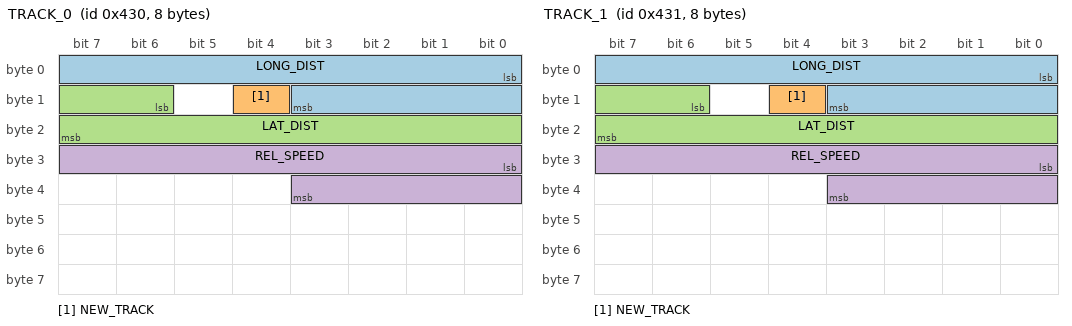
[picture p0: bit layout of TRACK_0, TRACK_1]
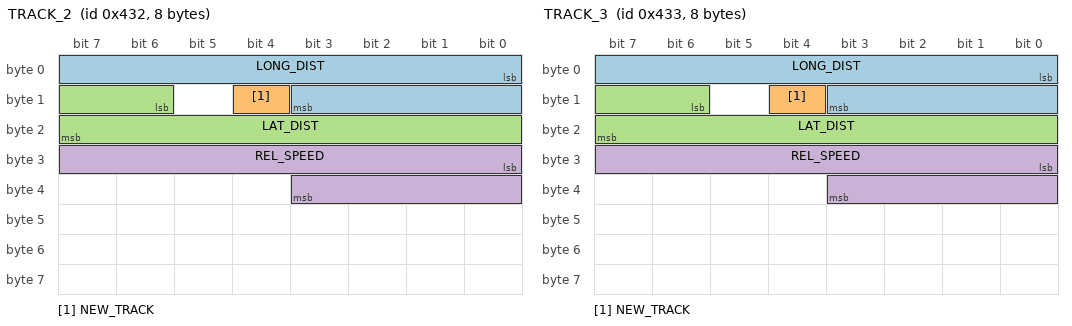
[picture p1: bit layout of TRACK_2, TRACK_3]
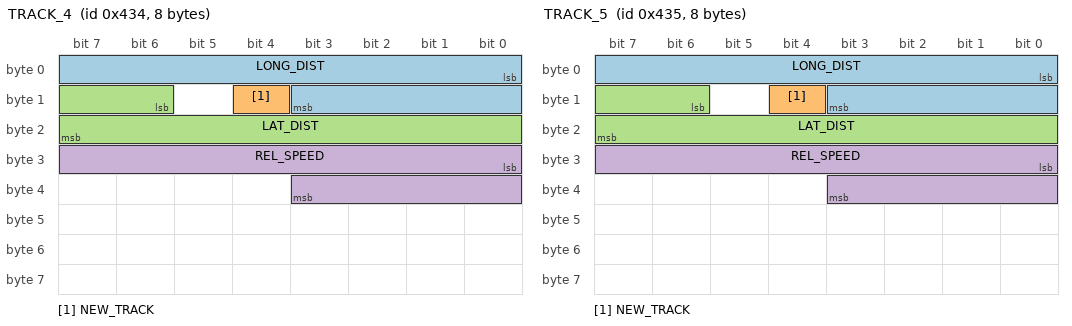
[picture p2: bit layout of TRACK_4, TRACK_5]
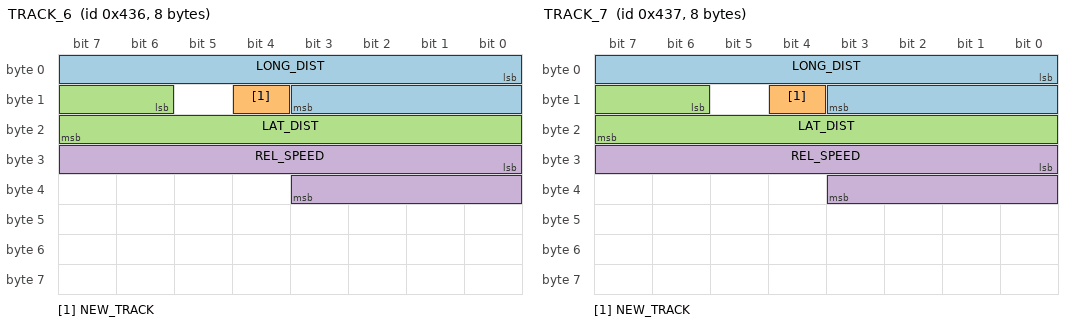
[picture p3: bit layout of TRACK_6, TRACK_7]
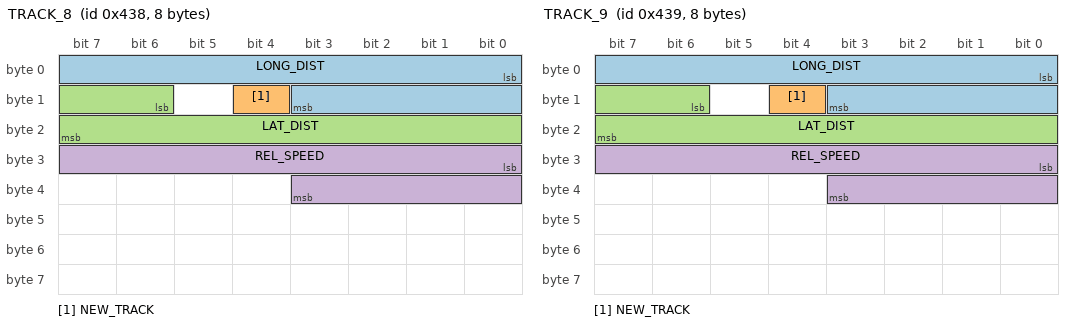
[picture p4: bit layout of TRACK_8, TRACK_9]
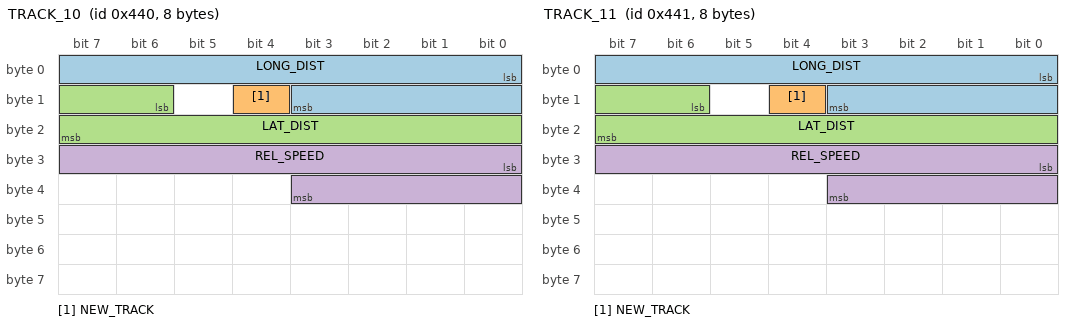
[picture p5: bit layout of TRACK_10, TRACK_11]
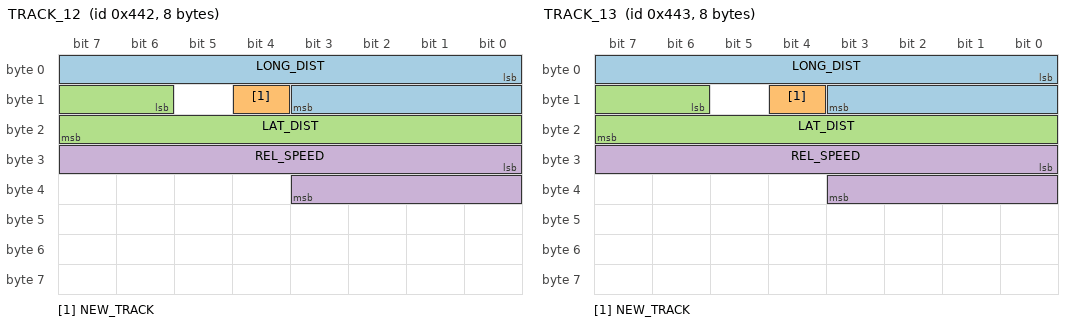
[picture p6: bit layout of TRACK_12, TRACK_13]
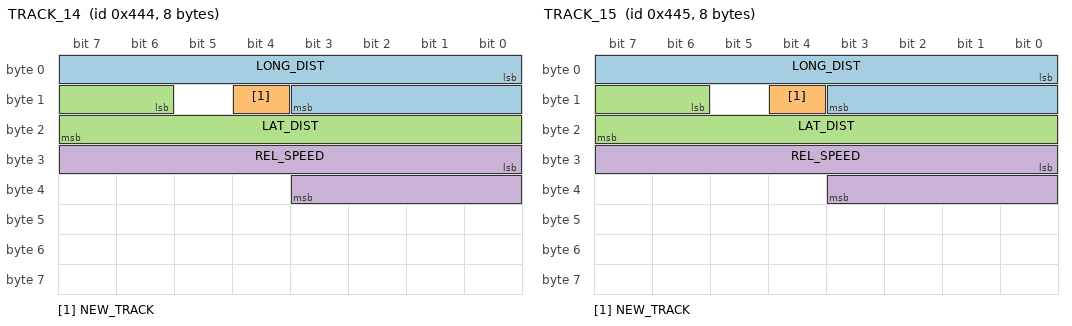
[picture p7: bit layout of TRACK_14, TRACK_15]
VERSION ""

NS_ :

BS_:

BO_ 0x300 VEHICLE_STATE: 8 ADAS
 SG_ SET_ME_XF9 : 0|8@1+ (1,0) [0|255] "" Vector__XXX
 SG_ VEHICLE_SPEED : 8|8@1+ (1,0) [0|255] "kph" Vector__XXX

BO_ 0x301 VEHICLE_STATE2: 8 ADAS
 SG_ SET_ME_0F18510 : 0|28@1+ (1,0) [0|268435455] "" Vector__XXX
 SG_ SET_ME_25A0000 : 28|28@1+ (1,0) [0|268435455] "" Vector__XXX

BO_ 0x400 XXX: 8 RADAR

BO_ 0x410 XXX: 8 RADAR

BO_ 0x411 XXX: 8 RADAR

BO_ 0x412 XXX: 8 RADAR

BO_ 0x413 XXX: 8 RADAR

BO_ 0x414 XXX: 8 RADAR

BO_ 0x415 XXX: 8 RADAR

BO_ 0x416 XXX: 8 RADAR

BO_ 0x417 XXX: 8 RADAR

BO_ 0x420 XXX: 8 RADAR

BO_ 0x421 XXX: 8 RADAR

BO_ 0x422 XXX: 8 RADAR

BO_ 0x423 XXX: 8 RADAR

BO_ 0x424 XXX: 8 RADAR

BO_ 0x430 TRACK_0: 8 RADAR
 SG_ LONG_DIST : 0|12@1+ (0.0625,0) [0|255.5] "m" Vector__XXX
 SG_ NEW_TRACK : 12|1@1+ (1,0) [0|1] "" Vector__XXX
 SG_ LAT_DIST : 14|10@1- (0.0625,0) [0|63.5] "m" Vector__XXX
 SG_ REL_SPEED : 24|12@1- (0.03125,0) [0|127.5] "m/s" Vector__XXX

BO_ 0x431 TRACK_1: 8 RADAR
 SG_ LONG_DIST : 0|12@1+ (0.0625,0) [0|255.5] "m" Vector__XXX
 SG_ NEW_TRACK : 12|1@1+ (1,0) [0|1] "" Vector__XXX
 SG_ LAT_DIST : 14|10@1- (0.0625,0) [0|63.5] "m" Vector__XXX
 SG_ REL_SPEED : 24|12@1- (0.03125,0) [0|127.5] "m/s" Vector__XXX

BO_ 0x432 TRACK_2: 8 RADAR
 SG_ LONG_DIST : 0|12@1+ (0.0625,0) [0|255.5] "m" Vector__XXX
 SG_ NEW_TRACK : 12|1@1+ (1,0) [0|1] "" Vector__XXX
 SG_ LAT_DIST : 14|10@1- (0.0625,0) [0|63.5] "m" Vector__XXX
 SG_ REL_SPEED : 24|12@1- (0.03125,0) [0|127.5] "m/s" Vector__XXX

BO_ 0x433 TRACK_3: 8 RADAR
 SG_ LONG_DIST : 0|12@1+ (0.0625,0) [0|255.5] "m" Vector__XXX
 SG_ NEW_TRACK : 12|1@1+ (1,0) [0|1] "" Vector__XXX
 SG_ LAT_DIST : 14|10@1- (0.0625,0) [0|63.5] "m" Vector__XXX
 SG_ REL_SPEED : 24|12@1- (0.03125,0) [0|127.5] "m/s" Vector__XXX

BO_ 0x434 TRACK_4: 8 RADAR
 SG_ LONG_DIST : 0|12@1+ (0.0625,0) [0|255.5] "m" Vector__XXX
 SG_ NEW_TRACK : 12|1@1+ (1,0) [0|1] "" Vector__XXX
 SG_ LAT_DIST : 14|10@1- (0.0625,0) [0|63.5] "m" Vector__XXX
 SG_ REL_SPEED : 24|12@1- (0.03125,0) [0|127.5] "m/s" Vector__XXX

BO_ 0x435 TRACK_5: 8 RADAR
 SG_ LONG_DIST : 0|12@1+ (0.0625,0) [0|255.5] "m" Vector__XXX
 SG_ NEW_TRACK : 12|1@1+ (1,0) [0|1] "" Vector__XXX
 SG_ LAT_DIST : 14|10@1- (0.0625,0) [0|63.5] "m" Vector__XXX
 SG_ REL_SPEED : 24|12@1- (0.03125,0) [0|127.5] "m/s" Vector__XXX

BO_ 0x436 TRACK_6: 8 RADAR
 SG_ LONG_DIST : 0|12@1+ (0.0625,0) [0|255.5] "m" Vector__XXX
 SG_ NEW_TRACK : 12|1@1+ (1,0) [0|1] "" Vector__XXX
 SG_ LAT_DIST : 14|10@1- (0.0625,0) [0|63.5] "m" Vector__XXX
 SG_ REL_SPEED : 24|12@1- (0.03125,0) [0|127.5] "m/s" Vector__XXX

BO_ 0x437 TRACK_7: 8 RADAR
 SG_ LONG_DIST : 0|12@1+ (0.0625,0) [0|255.5] "m" Vector__XXX
 SG_ NEW_TRACK : 12|1@1+ (1,0) [0|1] "" Vector__XXX
 SG_ LAT_DIST : 14|10@1- (0.0625,0) [0|63.5] "m" Vector__XXX
 SG_ REL_SPEED : 24|12@1- (0.03125,0) [0|127.5] "m/s" Vector__XXX

BO_ 0x438 TRACK_8: 8 RADAR
 SG_ LONG_DIST : 0|12@1+ (0.0625,0) [0|255.5] "m" Vector__XXX
 SG_ NEW_TRACK : 12|1@1+ (1,0) [0|1] "" Vector__XXX
 SG_ LAT_DIST : 14|10@1- (0.0625,0) [0|63.5] "m" Vector__XXX
 SG_ REL_SPEED : 24|12@1- (0.03125,0) [0|127.5] "m/s" Vector__XXX

BO_ 0x439 TRACK_9: 8 RADAR
 SG_ LONG_DIST : 0|12@1+ (0.0625,0) [0|255.5] "m" Vector__XXX
 SG_ NEW_TRACK : 12|1@1+ (1,0) [0|1] "" Vector__XXX
 SG_ LAT_DIST : 14|10@1- (0.0625,0) [0|63.5] "m" Vector__XXX
 SG_ REL_SPEED : 24|12@1- (0.03125,0) [0|127.5] "m/s" Vector__XXX

BO_ 0x440 TRACK_10: 8 RADAR
 SG_ LONG_DIST : 0|12@1+ (0.0625,0) [0|255.5] "m" Vector__XXX
 SG_ NEW_TRACK : 12|1@1+ (1,0) [0|1] "" Vector__XXX
 SG_ LAT_DIST : 14|10@1- (0.0625,0) [0|63.5] "m" Vector__XXX
 SG_ REL_SPEED : 24|12@1- (0.03125,0) [0|127.5] "m/s" Vector__XXX

BO_ 0x441 TRACK_11: 8 RADAR
 SG_ LONG_DIST : 0|12@1+ (0.0625,0) [0|255.5] "m" Vector__XXX
 SG_ NEW_TRACK : 12|1@1+ (1,0) [0|1] "" Vector__XXX
 SG_ LAT_DIST : 14|10@1- (0.0625,0) [0|63.5] "m" Vector__XXX
 SG_ REL_SPEED : 24|12@1- (0.03125,0) [0|127.5] "m/s" Vector__XXX

BO_ 0x442 TRACK_12: 8 RADAR
 SG_ LONG_DIST : 0|12@1+ (0.0625,0) [0|255.5] "m" Vector__XXX
 SG_ NEW_TRACK : 12|1@1+ (1,0) [0|1] "" Vector__XXX
 SG_ LAT_DIST : 14|10@1- (0.0625,0) [0|63.5] "m" Vector__XXX
 SG_ REL_SPEED : 24|12@1- (0.03125,0) [0|127.5] "m/s" Vector__XXX

BO_ 0x443 TRACK_13: 8 RADAR
 SG_ LONG_DIST : 0|12@1+ (0.0625,0) [0|255.5] "m" Vector__XXX
 SG_ NEW_TRACK : 12|1@1+ (1,0) [0|1] "" Vector__XXX
 SG_ LAT_DIST : 14|10@1- (0.0625,0) [0|63.5] "m" Vector__XXX
 SG_ REL_SPEED : 24|12@1- (0.03125,0) [0|127.5] "m/s" Vector__XXX

BO_ 0x444 TRACK_14: 8 RADAR
 SG_ LONG_DIST : 0|12@1+ (0.0625,0) [0|255.5] "m" Vector__XXX
 SG_ NEW_TRACK : 12|1@1+ (1,0) [0|1] "" Vector__XXX
 SG_ LAT_DIST : 14|10@1- (0.0625,0) [0|63.5] "m" Vector__XXX
 SG_ REL_SPEED : 24|12@1- (0.03125,0) [0|127.5] "m/s" Vector__XXX

BO_ 0x445 TRACK_15: 8 RADAR
 SG_ LONG_DIST : 0|12@1+ (0.0625,0) [0|255.5] "m" Vector__XXX
 SG_ NEW_TRACK : 12|1@1+ (1,0) [0|1] "" Vector__XXX
 SG_ LAT_DIST : 14|10@1- (0.0625,0) [0|63.5] "m" Vector__XXX
 SG_ REL_SPEED : 24|12@1- (0.03125,0) [0|127.5] "m/s" Vector__XXX

BO_ 0x4FF XXX: 8 RADAR

BO_ 0x500 XXX: 8 RADAR

BO_ 0x510 XXX: 8 RADAR

BO_ 0x511 XXX: 8 RADAR
